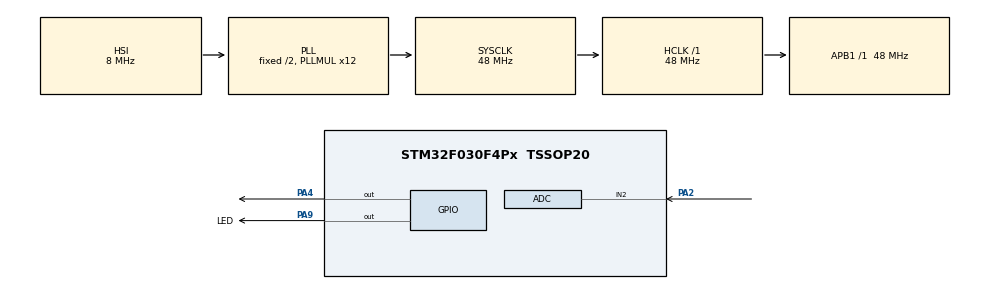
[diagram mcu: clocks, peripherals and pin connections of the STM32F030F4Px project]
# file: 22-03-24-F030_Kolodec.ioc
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ADC.ContinuousConvMode=ENABLE
ADC.SamplingTime=ADC_SAMPLETIME_13CYCLES_5
Dma.ADC.0.Direction=DMA_PERIPH_TO_MEMORY
Dma.ADC.0.Instance=DMA1_Channel1
Dma.ADC.0.MemDataAlignment=DMA_MDATAALIGN_HALFWORD
Dma.ADC.0.MemInc=DMA_MINC_ENABLE
Dma.ADC.0.Mode=DMA_NORMAL
Dma.ADC.0.PeriphDataAlignment=DMA_PDATAALIGN_HALFWORD
Dma.ADC.0.PeriphInc=DMA_PINC_DISABLE
Dma.ADC.0.Priority=DMA_PRIORITY_LOW
Dma.Request0=ADC
Mcu.Family=STM32F0
Mcu.Name=STM32F030F4Px
Mcu.Package=TSSOP20
NVIC.ADC1_IRQn=true\:0\:0\:false\:false\:true\:true\:true
NVIC.DMA1_Channel1_IRQn=true\:0\:0\:false\:false\:true\:false\:true
NVIC.TIM1_BRK_UP_TRG_COM_IRQn=true\:0\:0\:false\:false\:true\:true\:true
NVIC.TIM1_CC_IRQn=true\:0\:0\:false\:false\:true\:true\:true
PA13.Mode=Serial_Wire
PA13.Signal=SYS_SWDIO
PA14.Mode=Serial_Wire
PA14.Signal=SYS_SWCLK
PA2.Mode=IN2
PA2.Signal=ADC_IN2
PA4.Signal=GPIO_Output
PA9.GPIO_Label=LED
PA9.Signal=GPIO_Output
ProjectManager.HeapSize=0x200
ProjectManager.StackSize=0x400
ProjectManager.TargetToolchain=STM32CubeIDE
RCC.AHBFreq_Value=48000000
RCC.APB1Freq_Value=48000000
RCC.APB1TimFreq_Value=48000000
RCC.HCLKFreq_Value=48000000
RCC.PLLMUL=RCC_PLL_MUL12
RCC.SYSCLKFreq_VALUE=48000000
RCC.SYSCLKSource=RCC_SYSCLKSOURCE_PLLCLK
TIM1.Channel-Output\ Compare1\ No\ Output=TIM_CHANNEL_1
TIM1.Period=10000
TIM1.Prescaler=15
TIM3.Prescaler=47
VP_TIM1_VS_ClockSourceINT.Mode=Internal
VP_TIM1_VS_no_output1.Mode=Output Compare1 No Output
VP_TIM3_VS_ClockSourceINT.Mode=Internal
board=custom

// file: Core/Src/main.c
/* USER CODE BEGIN Header */
/**
 ******************************************************************************
 * @file           : main.c
 * @brief          : Main program body
 ******************************************************************************
 * @attention
 *
 * Copyright (c) 2022 STMicroelectronics.
 * All rights reserved.
 *
 * This software is licensed under terms that can be found in the LICENSE file
 * in the root directory of this software component.
 * If no LICENSE file comes with this software, it is provided AS-IS.
 *
 ******************************************************************************
 */
/* USER CODE END Header */
#include "main.h"

/* USER CODE BEGIN Includes */
#include "my_lib.h"
//#include "am2320.h"
#include "433_TX.h"

/* USER CODE END Includes */

ADC_HandleTypeDef hadc;
DMA_HandleTypeDef hdma_adc;

TIM_HandleTypeDef htim1;
TIM_HandleTypeDef htim3;

/* USER CODE BEGIN PV */
uint16_t bf[10];
uint32_t water;
GPIO_PinState pin9 = 0;
uint16_t *idBase0 = (uint16_t*) (UID_BASE);
uint16_t *idBase1 = (uint16_t*) (UID_BASE + 0x02);
uint32_t *idBase2 = (uint32_t*) (UID_BASE + 0x04);
uint32_t *idBase3 = (uint32_t*) (UID_BASE + 0x08);
int32_t id;

/* USER CODE END PV */

void SystemClock_Config(void);
static void MX_GPIO_Init(void);
static void MX_TIM3_Init(void);
static void MX_DMA_Init(void);
static void MX_ADC_Init(void);
static void MX_TIM1_Init(void);
/* USER CODE BEGIN PFP */
int make_buff(char *buff, uint8_t operation);
/* USER CODE END PFP */

int main(void)
{
  /* USER CODE BEGIN 1 */
	id = *idBase0 + *idBase1 + *idBase2 + *idBase3;
  /* USER CODE END 1 */

  /* MCU Configuration--------------------------------------------------------*/

  /* Reset of all peripherals, Initializes the Flash interface and the Systick. */
  HAL_Init();

  /* Configure the system clock */
  SystemClock_Config();

  /* Initialize all configured peripherals */
  MX_GPIO_Init();
  MX_TIM3_Init();
  MX_DMA_Init();
  MX_ADC_Init();
  MX_TIM1_Init();
  /* USER CODE BEGIN 2 */
  for (int i=0;i<20;i++){
	  HAL_GPIO_TogglePin(LED_GPIO_Port, LED_Pin);
	  HAL_Delay(50);
  }
	HAL_TIM_Base_Start(&htim3);
	HAL_TIM_Base_Start(&htim1);

  /* USER CODE END 2 */

  /* Infinite loop */
	while (1) {

    /* USER CODE BEGIN 3 */

		HAL_Delay(20000);

		HAL_ADC_Start_DMA(&hadc, bf, 10);
		HAL_Delay(1000);

		water=bf[0];
        for (int i=1;i<10;i++){
        	water+=bf[i];
        }
        water/=10;

        water=water_level(water);

		char *buff = d433_buff;
			buff = buff_copy(buff, "ID;", 3);
			buff = long_to_buff(buff, id);
			buff = buff_copy(buff, ";W;", 3);
			buff = long_to_buff(buff, (int16_t) water);
			HAL_GPIO_WritePin(LED_GPIO_Port, LED_Pin, 1);
			D433_sendData(d433_buff,buff-d433_buff);

			HAL_GPIO_WritePin(LED_GPIO_Port, LED_Pin, 0);

	}
  /* USER CODE END 3 */
}

void SystemClock_Config(void)
{
  RCC_OscInitTypeDef RCC_OscInitStruct = {0};
  RCC_ClkInitTypeDef RCC_ClkInitStruct = {0};

  /** Initializes the RCC Oscillators according to the specified parameters
  * in the RCC_OscInitTypeDef structure.
  */
  RCC_OscInitStruct.OscillatorType = RCC_OSCILLATORTYPE_HSI|RCC_OSCILLATORTYPE_HSI14;
  RCC_OscInitStruct.HSIState = RCC_HSI_ON;
  RCC_OscInitStruct.HSI14State = RCC_HSI14_ON;
  RCC_OscInitStruct.HSICalibrationValue = RCC_HSICALIBRATION_DEFAULT;
  RCC_OscInitStruct.HSI14CalibrationValue = 16;
  RCC_OscInitStruct.PLL.PLLState = RCC_PLL_ON;
  RCC_OscInitStruct.PLL.PLLSource = RCC_PLLSOURCE_HSI;
  RCC_OscInitStruct.PLL.PLLMUL = RCC_PLL_MUL12;
  RCC_OscInitStruct.PLL.PREDIV = RCC_PREDIV_DIV1;
  if (HAL_RCC_OscConfig(&RCC_OscInitStruct) != HAL_OK)
  {
    Error_Handler();
  }
  /** Initializes the CPU, AHB and APB buses clocks
  */
  RCC_ClkInitStruct.ClockType = RCC_CLOCKTYPE_HCLK|RCC_CLOCKTYPE_SYSCLK
                              |RCC_CLOCKTYPE_PCLK1;
  RCC_ClkInitStruct.SYSCLKSource = RCC_SYSCLKSOURCE_PLLCLK;
  RCC_ClkInitStruct.AHBCLKDivider = RCC_SYSCLK_DIV1;
  RCC_ClkInitStruct.APB1CLKDivider = RCC_HCLK_DIV1;

  if (HAL_RCC_ClockConfig(&RCC_ClkInitStruct, FLASH_LATENCY_1) != HAL_OK)
  {
    Error_Handler();
  }
}

static void MX_ADC_Init(void)
{

  ADC_ChannelConfTypeDef sConfig = {0};

  /** Configure the global features of the ADC (Clock, Resolution, Data Alignment and number of conversion)
  */
  hadc.Instance = ADC1;
  hadc.Init.ClockPrescaler = ADC_CLOCK_ASYNC_DIV1;
  hadc.Init.Resolution = ADC_RESOLUTION_12B;
  hadc.Init.DataAlign = ADC_DATAALIGN_RIGHT;
  hadc.Init.ScanConvMode = ADC_SCAN_DIRECTION_FORWARD;
  hadc.Init.EOCSelection = ADC_EOC_SINGLE_CONV;
  hadc.Init.LowPowerAutoWait = DISABLE;
  hadc.Init.LowPowerAutoPowerOff = DISABLE;
  hadc.Init.ContinuousConvMode = ENABLE;
  hadc.Init.DiscontinuousConvMode = DISABLE;
  hadc.Init.ExternalTrigConv = ADC_SOFTWARE_START;
  hadc.Init.ExternalTrigConvEdge = ADC_EXTERNALTRIGCONVEDGE_NONE;
  hadc.Init.DMAContinuousRequests = DISABLE;
  hadc.Init.Overrun = ADC_OVR_DATA_PRESERVED;
  if (HAL_ADC_Init(&hadc) != HAL_OK)
  {
    Error_Handler();
  }
  /** Configure for the selected ADC regular channel to be converted.
  */
  sConfig.Channel = ADC_CHANNEL_2;
  sConfig.Rank = ADC_RANK_CHANNEL_NUMBER;
  sConfig.SamplingTime = ADC_SAMPLETIME_13CYCLES_5;
  if (HAL_ADC_ConfigChannel(&hadc, &sConfig) != HAL_OK)
  {
    Error_Handler();
  }

}

static void MX_TIM1_Init(void)
{

  TIM_ClockConfigTypeDef sClockSourceConfig = {0};
  TIM_MasterConfigTypeDef sMasterConfig = {0};
  TIM_OC_InitTypeDef sConfigOC = {0};
  TIM_BreakDeadTimeConfigTypeDef sBreakDeadTimeConfig = {0};

  htim1.Instance = TIM1;
  htim1.Init.Prescaler = 15;
  htim1.Init.CounterMode = TIM_COUNTERMODE_UP;
  htim1.Init.Period = 10000;
  htim1.Init.ClockDivision = TIM_CLOCKDIVISION_DIV1;
  htim1.Init.RepetitionCounter = 0;
  htim1.Init.AutoReloadPreload = TIM_AUTORELOAD_PRELOAD_DISABLE;
  if (HAL_TIM_Base_Init(&htim1) != HAL_OK)
  {
    Error_Handler();
  }
  sClockSourceConfig.ClockSource = TIM_CLOCKSOURCE_INTERNAL;
  if (HAL_TIM_ConfigClockSource(&htim1, &sClockSourceConfig) != HAL_OK)
  {
    Error_Handler();
  }
  if (HAL_TIM_OC_Init(&htim1) != HAL_OK)
  {
    Error_Handler();
  }
  sMasterConfig.MasterOutputTrigger = TIM_TRGO_RESET;
  sMasterConfig.MasterSlaveMode = TIM_MASTERSLAVEMODE_DISABLE;
  if (HAL_TIMEx_MasterConfigSynchronization(&htim1, &sMasterConfig) != HAL_OK)
  {
    Error_Handler();
  }
  sConfigOC.OCMode = TIM_OCMODE_TIMING;
  sConfigOC.Pulse = 0;
  sConfigOC.OCPolarity = TIM_OCPOLARITY_HIGH;
  sConfigOC.OCNPolarity = TIM_OCNPOLARITY_HIGH;
  sConfigOC.OCFastMode = TIM_OCFAST_DISABLE;
  sConfigOC.OCIdleState = TIM_OCIDLESTATE_RESET;
  sConfigOC.OCNIdleState = TIM_OCNIDLESTATE_RESET;
  if (HAL_TIM_OC_ConfigChannel(&htim1, &sConfigOC, TIM_CHANNEL_1) != HAL_OK)
  {
    Error_Handler();
  }
  sBreakDeadTimeConfig.OffStateRunMode = TIM_OSSR_DISABLE;
  sBreakDeadTimeConfig.OffStateIDLEMode = TIM_OSSI_DISABLE;
  sBreakDeadTimeConfig.LockLevel = TIM_LOCKLEVEL_OFF;
  sBreakDeadTimeConfig.DeadTime = 0;
  sBreakDeadTimeConfig.BreakState = TIM_BREAK_DISABLE;
  sBreakDeadTimeConfig.BreakPolarity = TIM_BREAKPOLARITY_HIGH;
  sBreakDeadTimeConfig.AutomaticOutput = TIM_AUTOMATICOUTPUT_DISABLE;
  if (HAL_TIMEx_ConfigBreakDeadTime(&htim1, &sBreakDeadTimeConfig) != HAL_OK)
  {
    Error_Handler();
  }

}

static void MX_TIM3_Init(void)
{

  TIM_ClockConfigTypeDef sClockSourceConfig = {0};
  TIM_MasterConfigTypeDef sMasterConfig = {0};

  htim3.Instance = TIM3;
  htim3.Init.Prescaler = 47;
  htim3.Init.CounterMode = TIM_COUNTERMODE_UP;
  htim3.Init.Period = 65535;
  htim3.Init.ClockDivision = TIM_CLOCKDIVISION_DIV1;
  htim3.Init.AutoReloadPreload = TIM_AUTORELOAD_PRELOAD_DISABLE;
  if (HAL_TIM_Base_Init(&htim3) != HAL_OK)
  {
    Error_Handler();
  }
  sClockSourceConfig.ClockSource = TIM_CLOCKSOURCE_INTERNAL;
  if (HAL_TIM_ConfigClockSource(&htim3, &sClockSourceConfig) != HAL_OK)
  {
    Error_Handler();
  }
  sMasterConfig.MasterOutputTrigger = TIM_TRGO_RESET;
  sMasterConfig.MasterSlaveMode = TIM_MASTERSLAVEMODE_DISABLE;
  if (HAL_TIMEx_MasterConfigSynchronization(&htim3, &sMasterConfig) != HAL_OK)
  {
    Error_Handler();
  }

}

static void MX_DMA_Init(void)
{

  /* DMA controller clock enable */
  __HAL_RCC_DMA1_CLK_ENABLE();

  /* DMA interrupt init */
  /* DMA1_Channel1_IRQn interrupt configuration */
  HAL_NVIC_SetPriority(DMA1_Channel1_IRQn, 0, 0);
  HAL_NVIC_EnableIRQ(DMA1_Channel1_IRQn);

}

static void MX_GPIO_Init(void)
{
  GPIO_InitTypeDef GPIO_InitStruct = {0};

  /* GPIO Ports Clock Enable */
  __HAL_RCC_GPIOA_CLK_ENABLE();

  /*Configure GPIO pin Output Level */
  HAL_GPIO_WritePin(GPIOA, GPIO_PIN_4|LED_Pin, GPIO_PIN_RESET);

  /*Configure GPIO pins : PA4 LED_Pin */
  GPIO_InitStruct.Pin = GPIO_PIN_4|LED_Pin;
  GPIO_InitStruct.Mode = GPIO_MODE_OUTPUT_PP;
  GPIO_InitStruct.Pull = GPIO_NOPULL;
  GPIO_InitStruct.Speed = GPIO_SPEED_FREQ_LOW;
  HAL_GPIO_Init(GPIOA, &GPIO_InitStruct);

}

void Error_Handler(void)
{
	__disable_irq();
	while (1) {
	}
}
